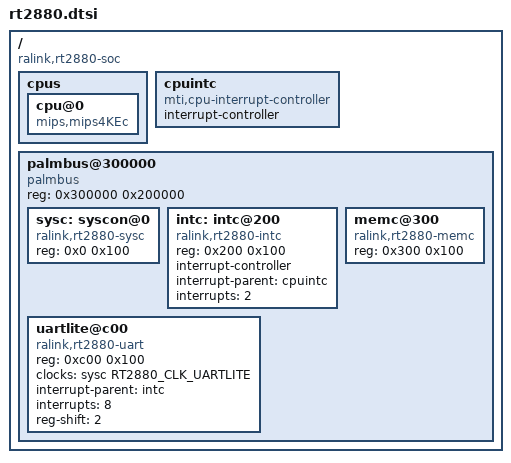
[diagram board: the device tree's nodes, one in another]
// SPDX-License-Identifier: GPL-2.0
#include <dt-bindings/clock/mediatek,mtmips-sysc.h>

/ {
	#address-cells = <1>;
	#size-cells = <1>;
	compatible = "ralink,rt2880-soc";

	cpus {
		cpu@0 {
			compatible = "mips,mips4KEc";
		};
	};

	cpuintc: cpuintc {
		#address-cells = <0>;
		#interrupt-cells = <1>;
		interrupt-controller;
		compatible = "mti,cpu-interrupt-controller";
	};

	palmbus@300000 {
		compatible = "palmbus";
		reg = <0x300000 0x200000>;
                ranges = <0x0 0x300000 0x1FFFFF>;

		#address-cells = <1>;
		#size-cells = <1>;

		sysc: syscon@0 {
			compatible = "ralink,rt2880-sysc", "syscon";
			reg = <0x0 0x100>;
			#clock-cells = <1>;
			#reset-cells = <1>;
		};

		intc: intc@200 {
			compatible = "ralink,rt2880-intc";
			reg = <0x200 0x100>;

			interrupt-controller;
			#interrupt-cells = <1>;

			interrupt-parent = <&cpuintc>;
			interrupts = <2>;
		};

		memc@300 {
			compatible = "ralink,rt2880-memc";
			reg = <0x300 0x100>;
		};

		uartlite@c00 {
			compatible = "ralink,rt2880-uart", "ns16550a";
			reg = <0xc00 0x100>;

			clocks = <&sysc RT2880_CLK_UARTLITE>;

			interrupt-parent = <&intc>;
			interrupts = <8>;

			reg-shift = <2>;
		};
	};
};
